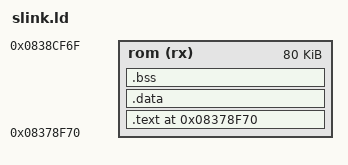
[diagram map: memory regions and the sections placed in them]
/* Generated by patch/tools/native_layout.py. No mutable implicit native storage. */
MEMORY { rom (rx) : ORIGIN = 0x08378F70, LENGTH = 0x14000 }
SECTIONS
{
  .text ORIGIN(rom) : { KEEP(*(.text.entry)) *(.text*) *(.rodata*) } > rom
  .data : { *(.data*) } > rom
  .bss (NOLOAD) : { *(.bss*) *(COMMON) } > rom
  ASSERT(SIZEOF(.data) == 0, "SLink native .data is forbidden: use explicit verified state")
  ASSERT(SIZEOF(.bss) == 0, "SLink native .bss/COMMON is forbidden: use explicit verified state")
  ASSERT(ADDR(.text) == ORIGIN(rom), "native entry placement drift")
  ASSERT(SIZEOF(.text) <= LENGTH(rom), "native code exceeds verified ROM range")
  /DISCARD/ : { *(.ARM.exidx*) *(.ARM.attributes) *(.comment) *(.note*) }
}
